# AltaRiscv register map
File version: 1.0
Registers are 32-bit, read-write, reset 0x0 unless marked. A register's access mark holds for its fields unless they carry their own. Offsets are from the block's base; [hi:lo] are bit positions; {n}, {i} and the like mark numbered series; 'fields as' and 'values as' point back to an identical list.

## GPIO0 — GPIO registers
Base 0x40014000
Same registers: GPIO{n} {0x40014000+0x1000*n} (n=1..9)
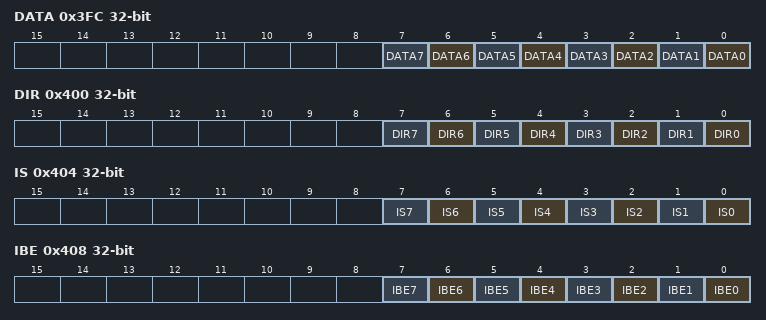
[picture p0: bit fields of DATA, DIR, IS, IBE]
0x3FC DATA
  [n] DATA{n} (n=0..7) — Data register bit {n}
0x400 DIR — Data direction register
  [all] fields
    0=Input; 1=Output
  [n] DIR{n} (n=0..7) — Data direction bit {n}
0x404 IS — Interrupt sense register
  [all] fields
    0=Edge; 1=Level
  [n] IS{n} (n=0..7) — Interrupt sense bit {n}
0x408 IBE — Interrupt both-edges register
  [all] fields
    0=Single Edge; 1=Both Edge
  [n] IBE{n} (n=0..7) — Interrupt both-edges bit {n}
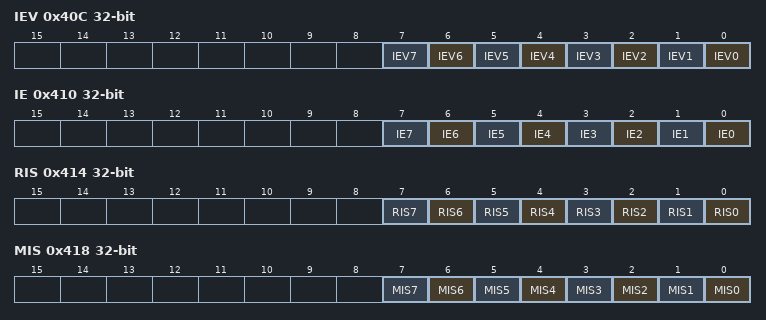
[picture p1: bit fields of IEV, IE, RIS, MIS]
0x40C IEV — Interrupt event register
  [all] fields
    0=Rising Edge/High Level; 1=Falling Edge/Low Level
  [n] IEV{n} (n=0..7) — Interrupt event bit {n}
0x410 IE — Interrupt mask register
  [n] IE{n} (n=0..7) — Interrupt mask bit {n}
0x414 RIS — Raw interrupt status register
  [n] RIS{n} (n=0..7) — Raw interrupt status bit {n}
0x418 MIS — Masked interrupt status register
  [n] MIS{n} (n=0..7) — Masked interrupt status bit {n}
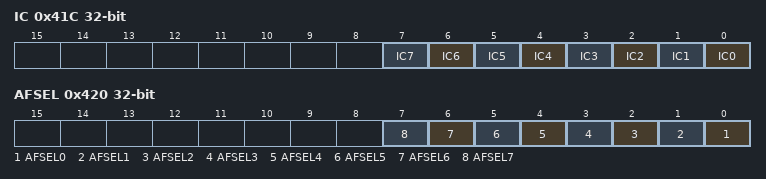
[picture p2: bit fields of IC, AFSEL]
0x41C IC — Interrupt clear register
  [n] IC{n} (n=0..7) — Interrupt clear bit {n}
0x420 AFSEL — Mode control select register
  [all] fields
    0=Software Mode; 1=Hardware Mode
  [n] AFSEL{n} (n=0..7) — Mode control select bit {n}

## TIMER0 — TIMER registers
Base 0x4001E000
Same registers: TIMER1 0x4001F000
0x00 Timer1Load — Load Register
0x04 Timer1Value ro — Current Value Register
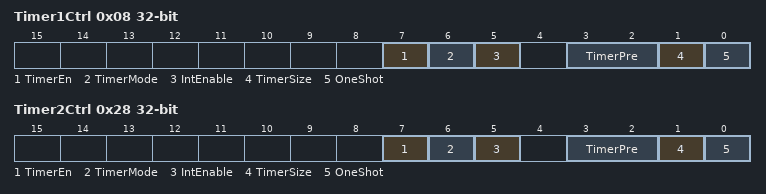
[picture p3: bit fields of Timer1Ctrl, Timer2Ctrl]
0x08 Timer1Ctrl — Control Register
  [7] TimerEn — Timer Enable
  [6] TimerMode
    0=Free-running; 1=Periodic
  [5] IntEnable — Interrupt enable
  [3:2] TimerPre — Prescaler bits
    0=Div 1; 1=Div 16; 2=Div 256
  [1] TimerSize
    0=16-bit; 1=32-bit
  [0] OneShot — One shot mode
0x0C Timer1IntClr wo — Interrupt Clear Register
  [0] Timer1IntClr
0x10 Timer1RIS ro — Raw Interrupt Status Register
  [0] Timer1RIS
0x14 Timer1MIS ro — Masked Interrupt Status Register
  [0] Timer1MIS
0x18 Timer1BGL — Background Load Register
0x20 Timer2Load — Load Register
0x24 Timer2Value ro — Current Value Register
0x28 Timer2Ctrl — Control Register
  fields as Timer1Ctrl
0x2C Timer2IntClr wo — Interrupt Clear Register
  [0] Timer2IntClr
0x30 Timer2RIS ro — Raw Interrupt Status Register
  [0] Timer2RIS
0x34 Timer2MIS ro — Masked Interrupt Status Register
  [0] Timer2MIS
0x38 Timer2BGL — Background Load Register

## UART0 — UART registers
Base 0x40025000
Same registers: UART1 0x40026000, UART2 0x40027000, UART3 0x40028000, UART4 0x40029000
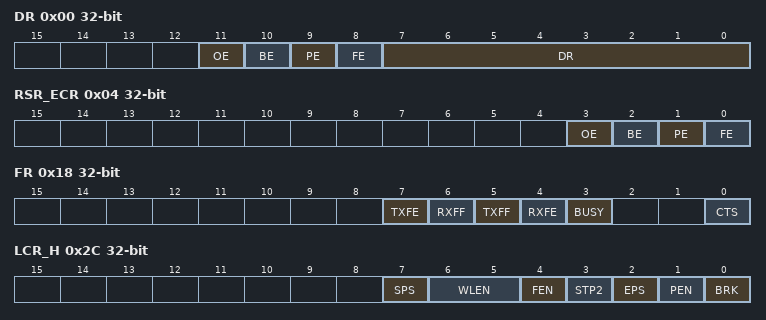
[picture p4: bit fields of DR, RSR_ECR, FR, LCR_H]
0x00 DR — Data register
  [11] OE — Overrun error
  [10] BE — Break error
  [9] PE — Parity error
  [8] FE — Framing error
  [7:0] DR — Data register
0x04 RSR_ECR — Receive status register/error clear register
  [3] OE — Overrun error
  [2] BE — Break error
  [1] PE — Parity error
  [0] FE — Framing error
0x18 FR ro — Flag register
  [7] TXFE — Transmit FIFO empty
  [6] RXFF — Receive FIFO full
  [5] TXFF — Transmit FIFO full
  [4] RXFE — Receive FIFO empty
  [3] BUSY — UART busy transmitting data
  [0] CTS — Clear to send
0x24 IBRD — Integer baud rate register
  [15:0] IBRD
0x28 FBRD — Fractional baud rate register
  [5:0] FBRD
0x2C LCR_H — Line control register
  [7] SPS — Stick parity select
  [6:5] WLEN — Word length, data bits in a frame
    {v}={v+5} bits (v=0..3)
  [4] FEN — Enable FIFOs
  [3] STP2 — Two stop bits select
    0=1 stop bit; 1=2 stop bits
  [2] EPS — Even parity select
    0=Odd parity; 1=Even parity
  [1] PEN — Parity enable
  [0] BRK — Send break
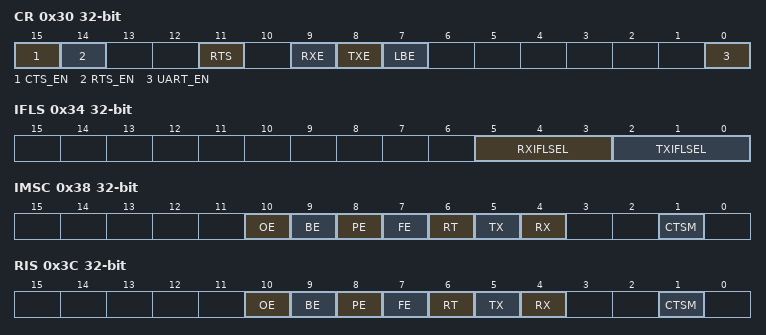
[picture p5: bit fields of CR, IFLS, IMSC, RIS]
0x30 CR — Control register
  [15] CTS_EN — CTS hardware flow control enable
  [14] RTS_EN — RTS hardware flow control enable
  [11] RTS — Request to send
  [9] RXE — Receive enable
  [8] TXE — Transmit enable
  [7] LBE — Loop back enable
  [0] UART_EN — UART enable
0x34 IFLS — Interrupt FIFO level select register
  [5:3] RXIFLSEL — Receive interrupt FIFO level select
    0=ge_1_8 (`>= 1/8`); 1=ge_1_4 (`>= 1/4`); 2=ge_1_2 (`>= 1/2`); 3=ge_3_4 (`>= 3/4`); 4=ge_7_8 (`>= 7/8`)
  [2:0] TXIFLSEL — Transmit interrupt FIFO level select
    values as RXIFLSEL
0x38 IMSC — Interrupt mask set/clear register
  [10] OE — Overrun error interrupt mask
  [9] BE — Break error interrupt mask
  [8] PE — Parity error interrupt mask
  [7] FE — Framing error interrupt mask
  [6] RT — Receive timeout interrupt mask
  [5] TX — Transmit interrupt mask
  [4] RX — Receive interrupt mask
  [1] CTSM — nUARTCTS modem interrupt mask
0x3C RIS — Raw interrupt status register
  [10] OE — Overrun error interrupt status
  [9] BE — Break error interrupt status
  [8] PE — Parity error interrupt status
  [7] FE — Framing error interrupt status
  [6] RT — Receive timeout interrupt status
  [5] TX — Transmit interrupt status
  [4] RX — Receive interrupt status
  [1] CTSM — nUARTCTS modem interrupt status
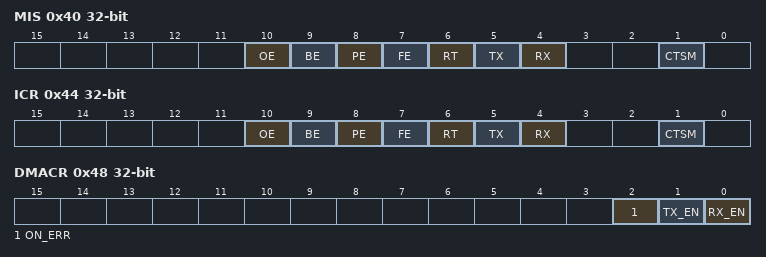
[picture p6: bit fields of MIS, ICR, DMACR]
0x40 MIS — Masked interrupt status register
  [10] OE — Overrun error masked interrupt status
  [9] BE — Break error masked interrupt status
  [8] PE — Parity error masked interrupt status
  [7] FE — Framing error masked interrupt status
  [6] RT — Receive timeout masked interrupt status
  [5] TX — Transmit masked interrupt status
  [4] RX — Receive masked interrupt status
  [1] CTSM — nUARTCTS modem masked interrupt status
0x44 ICR — Interrupt clear register
  [10] OE — Overrun error interrupt clear
  [9] BE — Break error interrupt clear
  [8] PE — Parity error interrupt clear
  [7] FE — Framing error interrupt clear
  [6] RT — Receive timeout interrupt clear
  [5] TX — Transmit interrupt clear
  [4] RX — Receive interrupt clear
  [1] CTSM — nUARTCTS modem interrupt clear
0x48 DMACR — DMA control register
  [2] ON_ERR — Stop DMA on error
  [1] TX_EN — Transmit DMA enable
  [0] RX_EN — Receive DMA enable
